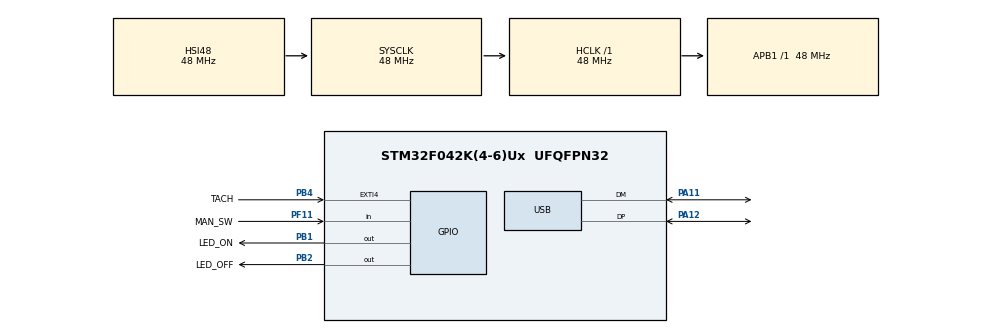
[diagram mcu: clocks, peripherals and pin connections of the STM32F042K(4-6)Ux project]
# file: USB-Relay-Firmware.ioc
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Mcu.Family=STM32F0
Mcu.Name=STM32F042K(4-6)Ux
Mcu.Package=UFQFPN32
NVIC.EXTI4_15_IRQn=true\:3\:0\:true\:false\:true\:true\:true\:true
NVIC.USB_IRQn=true\:0\:0\:false\:false\:true\:false\:true\:true
PA11.Mode=Device
PA11.Signal=USB_DM
PA12.Mode=Device
PA12.Signal=USB_DP
PA2.GPIO_Label=UART_TX
PA2.Signal=USART2_TX
PA3.GPIO_Label=UART_RX
PA3.Signal=USART2_RX
PA5.GPIO_Label=COIL_CTL
PA5.Signal=S_TIM2_CH1_ETR
PB1.GPIO_Label=LED_ON
PB1.Signal=GPIO_Output
PB2.GPIO_Label=LED_OFF
PB2.Signal=GPIO_Output
PB4.GPIO_Label=TACH
PB4.GPIO_ModeDefaultEXTI=GPIO_MODE_IT_FALLING
PB4.GPIO_PuPd=GPIO_PULLUP
PB4.Signal=GPXTI4
PF11.GPIO_Label=MAN_SW
PF11.Signal=GPIO_Input
ProjectManager.HeapSize=0x200
ProjectManager.StackSize=0x400
ProjectManager.TargetToolchain=STM32CubeIDE
RCC.AHBFreq_Value=48000000
RCC.APB1Freq_Value=48000000
RCC.APB1TimFreq_Value=48000000
RCC.HCLKFreq_Value=48000000
RCC.PLLSourceVirtual=RCC_PLLSOURCE_HSI
RCC.SYSCLKFreq_VALUE=48000000
RCC.SYSCLKSource=RCC_SYSCLKSOURCE_HSI48
RCC.USBFreq_Value=48000000
SH.S_TIM2_CH1_ETR.0=TIM2_CH1
USB_DEVICE.APP_RX_DATA_SIZE=64
USB_DEVICE.APP_TX_DATA_SIZE=64
USB_DEVICE.CLASS_NAME_FS=CDC
USB_DEVICE.MANUFACTURER_STRING=IT Logic
USB_DEVICE.PRODUCT_STRING_CDC_FS=USB Relay
USB_DEVICE.USBD_MAX_STR_DESC_SIZ=256
USB_DEVICE.VirtualMode=Cdc
USB_DEVICE.VirtualModeFS=Cdc_FS
VP_USB_DEVICE_VS_USB_DEVICE_CDC_FS.Mode=CDC_FS
board=custom

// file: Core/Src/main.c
/* USER CODE BEGIN Header */
/**
  ******************************************************************************
  * @file           : main.c
  * @brief          : Main program body
  ******************************************************************************
  * @attention
  *
  * Copyright (c) 2025 STMicroelectronics.
  * All rights reserved.
  *
  * This software is licensed under terms that can be found in the LICENSE file
  * in the root directory of this software component.
  * If no LICENSE file comes with this software, it is provided AS-IS.
  *
  ******************************************************************************
  */
/* USER CODE END Header */
#include "main.h"
#include "usb_device.h"

/* USER CODE BEGIN Includes */
#include "cmd_process.h"
/* USER CODE END Includes */

void SystemClock_Config(void);
static void MX_GPIO_Init(void);

/* USER CODE BEGIN 0 */
void HAL_GPIO_EXTI_Callback(uint16_t GPIO_Pin) {
	TachIncrement();
}
/* USER CODE END 0 */

int main(void)
{

  /* MCU Configuration--------------------------------------------------------*/

  /* Reset of all peripherals, Initializes the Flash interface and the Systick. */
  HAL_Init();

  /* Configure the system clock */
  SystemClock_Config();

  /* Initialize all configured peripherals */
  MX_GPIO_Init();
  MX_USB_DEVICE_Init();
  /* USER CODE BEGIN 2 */
  CmdParserInit(); // Initialize the data structure
  SetupTIM2();	// Manually Configure TIM2 CH2 in PWM Mode
  /* USER CODE END 2 */

  /* Infinite loop */
  /* USER CODE BEGIN WHILE */
  while (1)
  {
	UpdateLeds();	// Update the status led depending on coil
	CheckButton();
	CheckDelays();
    /* USER CODE END WHILE */

  }
}

void SystemClock_Config(void)
{
  RCC_OscInitTypeDef RCC_OscInitStruct = {0};
  RCC_ClkInitTypeDef RCC_ClkInitStruct = {0};
  RCC_PeriphCLKInitTypeDef PeriphClkInit = {0};

  /** Initializes the RCC Oscillators according to the specified parameters
  * in the RCC_OscInitTypeDef structure.
  */
  RCC_OscInitStruct.OscillatorType = RCC_OSCILLATORTYPE_HSI48;
  RCC_OscInitStruct.HSI48State = RCC_HSI48_ON;
  RCC_OscInitStruct.PLL.PLLState = RCC_PLL_NONE;
  if (HAL_RCC_OscConfig(&RCC_OscInitStruct) != HAL_OK)
  {
    Error_Handler();
  }

  /** Initializes the CPU, AHB and APB buses clocks
  */
  RCC_ClkInitStruct.ClockType = RCC_CLOCKTYPE_HCLK|RCC_CLOCKTYPE_SYSCLK
                              |RCC_CLOCKTYPE_PCLK1;
  RCC_ClkInitStruct.SYSCLKSource = RCC_SYSCLKSOURCE_HSI48;
  RCC_ClkInitStruct.AHBCLKDivider = RCC_SYSCLK_DIV1;
  RCC_ClkInitStruct.APB1CLKDivider = RCC_HCLK_DIV1;

  if (HAL_RCC_ClockConfig(&RCC_ClkInitStruct, FLASH_LATENCY_1) != HAL_OK)
  {
    Error_Handler();
  }
  PeriphClkInit.PeriphClockSelection = RCC_PERIPHCLK_USB;
  PeriphClkInit.UsbClockSelection = RCC_USBCLKSOURCE_HSI48;

  if (HAL_RCCEx_PeriphCLKConfig(&PeriphClkInit) != HAL_OK)
  {
    Error_Handler();
  }
}

static void MX_GPIO_Init(void)
{
  GPIO_InitTypeDef GPIO_InitStruct = {0};

  /* GPIO Ports Clock Enable */
  __HAL_RCC_GPIOA_CLK_ENABLE();
  __HAL_RCC_GPIOB_CLK_ENABLE();
  __HAL_RCC_GPIOF_CLK_ENABLE();

  /*Configure GPIO pin Output Level */
  HAL_GPIO_WritePin(GPIOB, LED_ON_Pin|LED_OFF_Pin, GPIO_PIN_RESET);

  /*Configure GPIO pins : UART_TX_Pin UART_RX_Pin */
  GPIO_InitStruct.Pin = UART_TX_Pin|UART_RX_Pin;
  GPIO_InitStruct.Mode = GPIO_MODE_AF_PP;
  GPIO_InitStruct.Pull = GPIO_NOPULL;
  GPIO_InitStruct.Speed = GPIO_SPEED_FREQ_HIGH;
  GPIO_InitStruct.Alternate = GPIO_AF1_USART2;
  HAL_GPIO_Init(GPIOA, &GPIO_InitStruct);

  /*Configure GPIO pin : COIL_CTL_Pin */
  GPIO_InitStruct.Pin = COIL_CTL_Pin;
  GPIO_InitStruct.Mode = GPIO_MODE_AF_PP;
  GPIO_InitStruct.Pull = GPIO_NOPULL;
  GPIO_InitStruct.Speed = GPIO_SPEED_FREQ_LOW;
  GPIO_InitStruct.Alternate = GPIO_AF2_TIM2;
  HAL_GPIO_Init(COIL_CTL_GPIO_Port, &GPIO_InitStruct);

  /*Configure GPIO pins : LED_ON_Pin LED_OFF_Pin */
  GPIO_InitStruct.Pin = LED_ON_Pin|LED_OFF_Pin;
  GPIO_InitStruct.Mode = GPIO_MODE_OUTPUT_PP;
  GPIO_InitStruct.Pull = GPIO_NOPULL;
  GPIO_InitStruct.Speed = GPIO_SPEED_FREQ_LOW;
  HAL_GPIO_Init(GPIOB, &GPIO_InitStruct);

  /*Configure GPIO pin : TACH_Pin */
  GPIO_InitStruct.Pin = TACH_Pin;
  GPIO_InitStruct.Mode = GPIO_MODE_IT_FALLING;
  GPIO_InitStruct.Pull = GPIO_PULLUP;
  HAL_GPIO_Init(TACH_GPIO_Port, &GPIO_InitStruct);

  /*Configure GPIO pin : MAN_SW_Pin */
  GPIO_InitStruct.Pin = MAN_SW_Pin;
  GPIO_InitStruct.Mode = GPIO_MODE_INPUT;
  GPIO_InitStruct.Pull = GPIO_NOPULL;
  HAL_GPIO_Init(MAN_SW_GPIO_Port, &GPIO_InitStruct);

  /* EXTI interrupt init*/
  HAL_NVIC_SetPriority(EXTI4_15_IRQn, 3, 0);
  HAL_NVIC_EnableIRQ(EXTI4_15_IRQn);

}

void Error_Handler(void)
{
  __disable_irq();
  while (1)
  {
  }
}
